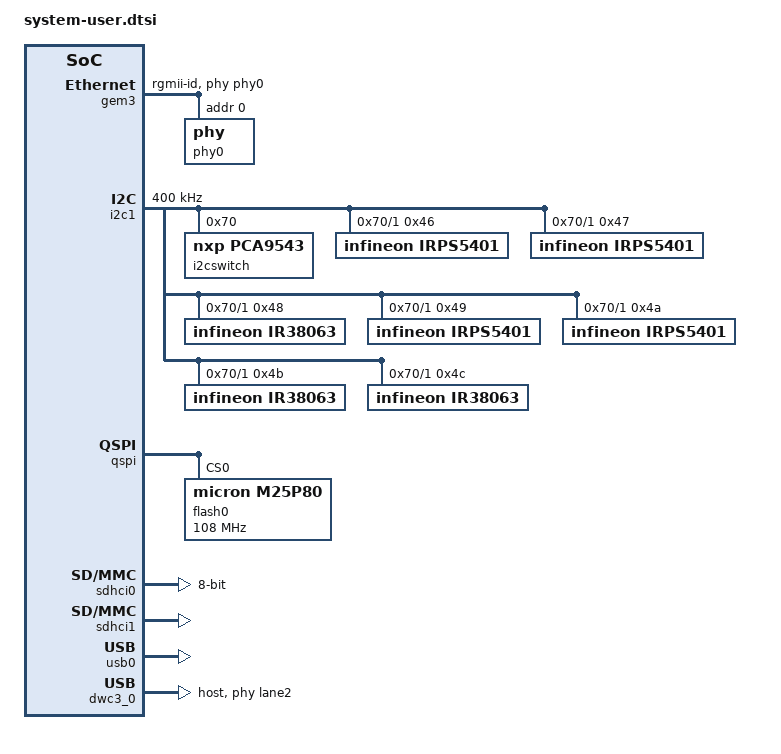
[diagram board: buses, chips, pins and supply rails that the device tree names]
/include/ "system-conf.dtsi"
/ {
   xlnk {
      compatible = "xlnx,xlnk-1.0";
   };
};

&gem3 {
	status = "okay";
	local-mac-address = [00 0a 35 00 02 90];
	phy-mode = "rgmii-id";
	phy-handle = <&phy0>;
	phy0: phy@0 {
		reg = <0x0>;
		ti,rx-internal-delay = <0x5>;
		ti,tx-internal-delay = <0x5>;
		ti,fifo-depth = <0x1>;
	};
};

&i2c1 {
	status = "okay";
	clock-frequency = <400000>;

	i2cswitch@70 { /* U7 on UZ3EG SOM, U8 on UZ7EV SOM */
		compatible = "nxp,pca9543";
		#address-cells = <1>;
		#size-cells = <0>;
		reg = <0x70>;
		i2c@0 { /* i2c mw 70 0 1 */
			#address-cells = <1>;
			#size-cells = <0>;
			reg = <0>;
			/*
			// Ethernet MAC ID EEPROM
			mac_eeprom@51 { // U5 on UZ3EG IOCC and U7 on the UZ7EV EVCC
				compatible = "at,24c08";
				reg = <0x51>;
			};
			// CLOCK2 CONFIG EEPROM
			clock_eeprom@52 { // U5 on the UZ7EV EVCC
				compatible = "at,24c08";
				reg = <0x52>;
			};
			*/
		};

		i2c@1 {
			#address-cells = <0x1>;
			#size-cells = <0x0>;
			reg = <0x1>;

			irps5401@46 {
				compatible = "infineon,irps5401";
				reg = <0x46>;
			};

			irps5401@47 {
				compatible = "infineon,irps5401";
				reg = <0x47>;
			};

			ir38063@48 {
				compatible = "infineon,ir38063";
				reg = <0x48>;
			};

			irps5401@49 {
				compatible = "infineon,irps5401";
				reg = <0x49>;
			};
			irps5401@4a {
				compatible = "infineon,irps5401";
				reg = <0x4a>;
			};

			ir38063@4b {
				compatible = "infineon,ir38063";
				reg = <0x4b>;
			};

			ir38063@4c {
				compatible = "infineon,ir38063";
				reg = <0x4c>;
			};
		};
	};
};

&qspi {
	#address-cells = <1>;
	#size-cells = <0>;
	status = "okay";
	is-dual = <1>; /* Set for dual-parallel QSPI config */
	num-cs = <2>;
	xlnx,fb-clk = <0x1>;
	flash0: flash@0 {
        /* The Flash described below doesn't match our board ("micron,n25qu256a"), but is needed */
        /* so the Flash MTD partitions are correctly identified in /proc/mtd */
		compatible = "micron,m25p80"; /* 32MB */
		#address-cells = <1>;
		#size-cells = <1>;
		reg = <0x0>;
		spi-tx-bus-width = <1>;
		spi-rx-bus-width = <4>; /* FIXME also DUAL configuration possible */
		spi-max-frequency = <108000000>; /* Set to 108000000 Based on DC1 spec */
	};
};

/* SD0 eMMC, 8-bit wide data bus */
&sdhci0 {
	status = "okay";
	bus-width = <8>;
	max-frequency = <50000000>;
};

/* SD1 with level shifter */
&sdhci1 {
	status = "okay";
	max-frequency = <50000000>;
	no-1-8-v;	/* for 1.0 silicon */
};

/* ULPI SMSC USB3320 */
&usb0 {
	status = "okay";
};

&dwc3_0 {
	status = "okay";
	dr_mode = "host";
	phy-names = "usb3-phy";
    snps,usb3_lpm_capable;
    phys = <&lane2 4 0 2 52000000>;
};

&amba {
	usb1@ff9e0000 {
		dwc3@fe300000 {
		snps,enable_auto_retry;
		};
	};
};

&amba_pl {
   // Remove definitions auto-generated by device tree generator
   /delete-node/interrupt-controller@a0030000; // axi_intc_0
};

&amba {
	axi_intc_0: axi-interrupt-ctrl {
		#interrupt-cells = <2>;
		compatible = "xlnx,xps-intc-1.00.a";
		interrupt-controller;
		reg = <0x0 0xa0030000 0x0 0x1000>;
		xlnx,kind-of-intr = <0x0>;
		xlnx,num-intr-inputs = <0x20>;
		interrupt-parent = <&gic>;
		// connected at pl_ps_irq0[5] (89+5=94) 
		interrupts = <0 94 4>;
	};

   zyxclmm_drm {
		compatible = "xlnx,zocl";
		status = "okay";
		interrupt-parent = <&axi_intc_0>;
		interrupts = <0  4>, <1  4>, <2  4>, <3  4>,
			     <4  4>, <5  4>, <6  4>, <7  4>,
			     <8  4>, <9  4>, <10 4>, <11 4>,
			     <12 4>, <13 4>, <14 4>, <15 4>,
			     <16 4>, <17 4>, <18 4>, <19 4>,
			     <20 4>, <21 4>, <22 4>, <23 4>,
			     <24 4>, <25 4>, <26 4>, <27 4>,
			     <28 4>, <29 4>, <30 4>, <31 4>;
	};

};



